AUTOSAR XML (schema 4-3-0)
package /Impl_SWC_OUTP_ARPkg
  swc implementation Impl_SWC_OUTP_type: programming-language=C, sw-version=1.0.0, vendor-id=0, behavior=SWC_OUTP_type_IB
    code-descriptors:
      code SRC: artifact-descriptors=autosar-engineering-object={short-label=EngObject, category=SWSRC}
    resource consumption ResourceConsumption
      memory section Mem_SWC_OUTP_CAL: size=0, sw-addrmethod=CAL, symbol=CAL
      memory section Mem_SWC_OUTP_CODE: size=0, sw-addrmethod=CODE, symbol=CODE
package /Impl_Type_OUTP_ARPkg
  6 x impl type:
    BOUTP_outputs: category=STRUCTURE
      956 x element, all with category=TYPE_REFERENCE:
        VOUTP_EACEnDemand_enum: implementation-data-type=uint8
        VOUTP_CACTempOverHigh_flg: implementation-data-type=boolean
        VOUTP_CACPresWarn_flg: implementation-data-type=boolean
        VOUTP_CACPresReady_flg: implementation-data-type=boolean
        VOUTP_EHPSEnDemand_enum: implementation-data-type=uint8
        VOUTP_CACOverrun_flg: implementation-data-type=boolean
        VOUTP_CACRunFail_flg: implementation-data-type=boolean
        VOUTP_CACFanReq_flg: implementation-data-type=boolean
        VOUTP_EHPSMotorDemSpd_rpm: implementation-data-type=float32
        VOUTP_EHPSSpdDemTimeout_flg: implementation-data-type=boolean
        VOUTP_EHPSEnTimeout_flg: implementation-data-type=boolean
        VOUTP_EHPSDisEnTimeout_flg: implementation-data-type=boolean
        VOUTP_DCDCEnDemamd_enum: implementation-data-type=uint8
        VOUTP_EHPSSpdCtrlMode_enum: implementation-data-type=float32
        VOUTP_EACSpdDemand_rpm: implementation-data-type=float32
        VOUTP_VehSpeed_kph: implementation-data-type=float32
        VOUTP_VehSpeedTimeOut_flg: implementation-data-type=boolean
        VOUTP_FSOffSw_enum: implementation-data-type=uint8
        VOUTP_FSOffSwTimeOut_flg: implementation-data-type=boolean
        VOUTP_ChrgPlugSta_enum: implementation-data-type=uint8
        VOUTP_PASDRMR_cm: implementation-data-type=uint8
        VOUTP_PASDRML_cm: implementation-data-type=uint8
        VOUTP_PASDRCR_cm: implementation-data-type=uint8
        VOUTP_PASDRCL_cm: implementation-data-type=uint8
        VOUTP_PASDFMR_cm: implementation-data-type=uint8
        VOUTP_PASDFML_cm: implementation-data-type=uint8
        VOUTP_PASDFCR_cm: implementation-data-type=uint8
        VOUTP_PASDFCL_cm: implementation-data-type=uint8
        VOUTP_APSDRLR_cm: implementation-data-type=uint16
        VOUTP_APSDRLL_cm: implementation-data-type=uint16
        VOUTP_APSDFLR_cm: implementation-data-type=uint16
        VOUTP_APSDFLL_cm: implementation-data-type=uint16
        VOUTP_PASAFCL_enum: implementation-data-type=uint8
        VOUTP_PASARMR_enum: implementation-data-type=uint8
        VOUTP_PASARML_enum: implementation-data-type=uint8
        VOUTP_PASARCR_enum: implementation-data-type=uint8
        VOUTP_PASARCL_enum: implementation-data-type=uint8
        VOUTP_PASAFMR_enum: implementation-data-type=uint8
        VOUTP_PASAFML_enum: implementation-data-type=uint8
        VOUTP_PASAFCR_enum: implementation-data-type=uint8
        VOUTP_USSStaRMR_flg: implementation-data-type=boolean
        VOUTP_USSStaRML_flg: implementation-data-type=boolean
        VOUTP_USSStaRLR_flg: implementation-data-type=boolean
        VOUTP_USSStaRLL_flg: implementation-data-type=boolean
        VOUTP_USSStaRCR_flg: implementation-data-type=boolean
        VOUTP_USSStaRCL_flg: implementation-data-type=boolean
        VOUTP_USSStaFMR_flg: implementation-data-type=boolean
        VOUTP_USSStaFML_flg: implementation-data-type=boolean
        VOUTP_USSStaFLR_flg: implementation-data-type=boolean
        VOUTP_USSStaFLL_flg: implementation-data-type=boolean
        VOUTP_USSStaFCR_flg: implementation-data-type=boolean
        VOUTP_USSStaFCL_flg: implementation-data-type=boolean
        VOUTP_Chime_enum: implementation-data-type=uint8
        VOUTP_SNSRLayout_enum: implementation-data-type=uint8
        VOUTP_StaFSya_flg: implementation-data-type=boolean
        VOUTP_ModOperation_enum: implementation-data-type=uint8
        VOUTP_BrkPedalPos_pct: implementation-data-type=float32
        VOUTP_BrkPedalPosTimeOut_flg: implementation-data-type=boolean
        VOUTP_LFRawWhlSpeed_kph: implementation-data-type=float32
        VOUTP_LFRawWhlSpeedTimeOut_flg: implementation-data-type=boolean
        VOUTP_RFRawWhlSpeed_kph: implementation-data-type=float32
        VOUTP_RFRawWhlSpeedTimeOut_flg: implementation-data-type=boolean
        VOUTP_LRRawWhlSpeed_kph: implementation-data-type=float32
        VOUTP_LRRawWhlSpeedTimeOut_flg: implementation-data-type=boolean
        VOUTP_RRRawWhlSpeed_kph: implementation-data-type=float32
        VOUTP_RRRawWhlSpeedTimeOut_flg: implementation-data-type=boolean
        VOUTP_LFRawWhlSpeedV_flg: implementation-data-type=boolean
        VOUTP_LFRawWhlSpeedVTimeOut_flg: implementation-data-type=boolean
        VOUTP_RFRawWhlSpeedV_flg: implementation-data-type=boolean
        VOUTP_RFRawWhlSpeedVTimeOut_flg: implementation-data-type=boolean
        VOUTP_LRRawWhlSpeedV_flg: implementation-data-type=boolean
        VOUTP_LRRawWhlSpeedVTimeOut_flg: implementation-data-type=boolean
        VOUTP_RRRawWhlSpeedV_flg: implementation-data-type=boolean
        VOUTP_RRRawWhlSpeedVTimeOut_flg: implementation-data-type=boolean
        VOUTP_LFWhlRotDir_enum: implementation-data-type=uint8
        VOUTP_LFWhlRotDirTimeOut_flg: implementation-data-type=boolean
        VOUTP_RFWhlRotDir_enum: implementation-data-type=uint8
        VOUTP_RFWhlRotDirTimeOut_flg: implementation-data-type=boolean
        VOUTP_LRWhlRotDir_enum: implementation-data-type=uint8
        VOUTP_LRWhlRotDirTimeOut_flg: implementation-data-type=boolean
        VOUTP_RRWhlRotDir_enum: implementation-data-type=uint8
        VOUTP_RRWhlRotDirTimeOut_flg: implementation-data-type=boolean
        VOUTP_LFPulseCountV_flg: implementation-data-type=boolean
        VOUTP_LFPulseCountVTimeOut_flg: implementation-data-type=boolean
        VOUTP_RFPulseCountV_flg: implementation-data-type=boolean
        VOUTP_RFPulseCountVTimeOut_flg: implementation-data-type=boolean
        VOUTP_LRPulseCountV_flg: implementation-data-type=boolean
        VOUTP_LRPulseCountVTimeOut_flg: implementation-data-type=boolean
        VOUTP_RRPulseCountV_flg: implementation-data-type=boolean
        VOUTP_RRPulseCountVTimeOut_flg: implementation-data-type=boolean
        VOUTP_LFPulseCount_enum: implementation-data-type=uint8
        VOUTP_LFPulseCountTimeOut_flg: implementation-data-type=boolean
        VOUTP_RFPulseCount_enum: implementation-data-type=uint8
        VOUTP_RFPulseCountTimeOut_flg: implementation-data-type=boolean
        VOUTP_LRPulseCount_enum: implementation-data-type=uint8
        VOUTP_LRPulseCountTimeOut_flg: implementation-data-type=boolean
        VOUTP_RRPulseCount_enum: implementation-data-type=uint8
        VOUTP_RRPulseCountTimeOut_flg: implementation-data-type=boolean
        VOUTP_ShifterHandleCmd_enum: implementation-data-type=uint8
        VOUTP_ShifterHandleCmdTimeOut_flg: implementation-data-type=boolean
        VOUTP_DriIntend_enum: implementation-data-type=uint8
        VOUTP_DriIntendTimeOut_flg: implementation-data-type=boolean
        VOUTP_EPSAOIControl_enum: implementation-data-type=uint8
        VOUTP_EPSAOIControlTimeOut_flg: implementation-data-type=boolean
        VOUTP_SASAngle_Deg: implementation-data-type=float32
        VOUTP_SASAngleTimeOut_flg: implementation-data-type=boolean
        VOUTP_SASSpeed_degps: implementation-data-type=float32
        VOUTP_SASSpeedTimeOut_flg: implementation-data-type=boolean
        VOUTP_SASSpeedValid_flg: implementation-data-type=boolean
        VOUTP_SASSpeedValidTimeOut_flg: implementation-data-type=boolean
        VOUTP_SASCAL_flg: implementation-data-type=boolean
        VOUTP_SASCALTimeOut_flg: implementation-data-type=boolean
        VOUTP_SASV_flg: implementation-data-type=boolean
        VOUTP_SASVTimeOut_flg: implementation-data-type=boolean
        VOUTP_GRADE_Deg: implementation-data-type=float32
        VOUTP_GRADETimeOut_flg: implementation-data-type=boolean
        VOUTP_YawRate_degps: implementation-data-type=float32
        VOUTP_YawRateTimeOut_flg: implementation-data-type=boolean
        VOUTP_LatAccel_Gps: implementation-data-type=float32
        VOUTP_LatAccelTimeOut_flg: implementation-data-type=boolean
        VOUTP_LongAccel_Gps: implementation-data-type=float32
        VOUTP_LongAccelTimeOut_flg: implementation-data-type=boolean
        VOUTP_MCPressure_bar: implementation-data-type=float32
        VOUTP_MCPressureTimeOut_flg: implementation-data-type=boolean
        VOUTP_YawRateV_flg: implementation-data-type=boolean
        VOUTP_YawRateVTimeOut_flg: implementation-data-type=boolean
        VOUTP_LatAccelV_flg: implementation-data-type=boolean
        VOUTP_LatAccelVTimeOut_flg: implementation-data-type=boolean
        VOUTP_LongAccelV_flg: implementation-data-type=boolean
        VOUTP_LongAccelVTimeOut_flg: implementation-data-type=boolean
        VOUTP_MCPressureV_bar: implementation-data-type=boolean
        VOUTP_MCPressureVTimeOut_flg: implementation-data-type=boolean
        VOUTP_BrkSwSta_flg: implementation-data-type=boolean
        VOUTP_BrkSwStaTimeOut_flg: implementation-data-type=boolean
        VOUTP_BrkSwV_flg: implementation-data-type=boolean
        VOUTP_BrkSwVTimeOut_flg: implementation-data-type=boolean
        VOUTP_ESCStandstill_flg: implementation-data-type=boolean
        VOUTP_ESCStandstillTimeOut_flg: implementation-data-type=boolean
        VOUTP_ESCAPSSta_enum: implementation-data-type=uint8
        VOUTP_ESCAPSStaTimeOut_flg: implementation-data-type=boolean
        VOUTP_EPBExtReleaseAvail_flg: implementation-data-type=boolean
        VOUTP_EPBExtReleaseAvailTimeOut_flg: implementation-data-type=boolean
        VOUTP_EPBExtApplyAvail_flg: implementation-data-type=boolean
        VOUTP_EPBExtApplyAvailTimeOut_flg: implementation-data-type=boolean
        VOUTP_EPBErrSta_enum: implementation-data-type=uint8
        VOUTP_EPBErrStaTimeOut_flg: implementation-data-type=boolean
        VOUTP_EPBSta_enum: implementation-data-type=uint8
        VOUTP_EPBStaTimeOut_flg: implementation-data-type=boolean
        VOUTP_AVMparkingcancel_enum: implementation-data-type=uint8
        VOUTP_AVMparkingcancelTimeOut_flg: implementation-data-type=boolean
        VOUTP_AVMparkingexcute_enum: implementation-data-type=uint8
        VOUTP_AVMparkingexcuteTimeOut_flg: implementation-data-type=boolean
        VOUTP_AVMParkingmode_enum: implementation-data-type=uint8
        VOUTP_AVMParkingmodeTimeOut_flg: implementation-data-type=boolean
        VOUTP_AVMErrSTA_flg: implementation-data-type=boolean
        VOUTP_AVMErrSTATimeOut_flg: implementation-data-type=boolean
        VOUTP_IVIStatus_flg: implementation-data-type=boolean
        VOUTP_IVIStatusTimeOut_flg: implementation-data-type=boolean
        VOUTP_CAASSw_enum: implementation-data-type=uint8
        VOUTP_CAASSwTimeOut_flg: implementation-data-type=boolean
        VOUTP_IVIScreen_enum: implementation-data-type=uint8
        VOUTP_IVIScreenTimeOut_flg: implementation-data-type=boolean
        VOUTP_ABSActive_flg: implementation-data-type=boolean
        VOUTP_ABSActiveTimeOut_flg: implementation-data-type=boolean
        VOUTP_TCSActive_flg: implementation-data-type=boolean
        VOUTP_TCSActiveTimeOut_flg: implementation-data-type=boolean
        VOUTP_DriverSeatBeltCmd_flg: implementation-data-type=boolean
        VOUTP_DriverSeatBeltCmdTimeOut_flg: implementation-data-type=boolean
        VOUTP_APSProgressPCT_pct: implementation-data-type=float32
        VOUTP_APSRQDisplay_enum: implementation-data-type=uint8
        VOUTP_APSSWVer_enum: implementation-data-type=uint8
        VOUTP_APSHWVer_enum: implementation-data-type=uint8
        VOUTP_APSExitCondition_enum: implementation-data-type=uint8
        VOUTP_APSAngleTarget_Deg: implementation-data-type=float32
        VOUTP_APSVRqEPASCtrl_flg: implementation-data-type=boolean
        VOUTP_APSRqEPASCtrl_flg: implementation-data-type=boolean
        VOUTP_CAASSta_enum: implementation-data-type=uint8
        VOUTP_DKCPDkeyAreaRAPSSta_enum: implementation-data-type=uint8
        VOUTP_DKCParkingModeCmd_enum: implementation-data-type=uint8
        VOUTP_PUIDLowPower_flg: implementation-data-type=boolean
        VOUTP_CAASVMCReqA_flg: implementation-data-type=boolean
        VOUTP_APSShiftPosnReq_enum: implementation-data-type=uint8
        VOUTP_APSSpeedCMD_kph: implementation-data-type=float32
        VOUTP_APSVMCReqA_flg: implementation-data-type=boolean
        VOUTP_RAPSBCMLamp_enum: implementation-data-type=uint8
        VOUTP_RAPSBCMLockReq_flg: implementation-data-type=boolean
        VOUTP_APSPwrReq_enum: implementation-data-type=uint8
        VOUTP_RAPSErrWarnSta_enum: implementation-data-type=uint8
        VOUTP_RAPSErrLv1_flg: implementation-data-type=boolean
        VOUTP_IVIUserTakeOverAPSSta_flg: implementation-data-type=boolean
        VOUTP_FDCBCMLBeamCmd_flg: implementation-data-type=boolean
        VOUTP_FDCBCMPLampCmd_flg: implementation-data-type=boolean
        VOUTP_FDCBCMHBeamCmd_flg: implementation-data-type=boolean
        VOUTP_FDCBCMSMKLCmd_flg: implementation-data-type=boolean
        VOUTP_FDCBCMSMKRCmd_flg: implementation-data-type=boolean
        VOUTP_FDCBCMDVRSignalLCmd_flg: implementation-data-type=boolean
        VOUTP_FDCBCMDVRSignalRCmd_flg: implementation-data-type=boolean
        VOUTP_FDCBCMBSDBuzzerCmd_flg: implementation-data-type=boolean
        VOUTP_FDCBCMSLTLpCmd_flg: implementation-data-type=boolean
        VOUTP_FDCBCMSRTLpCmd_flg: implementation-data-type=boolean
        VOUTP_FDCBCMLTurnLpCmd_flg: implementation-data-type=boolean
        VOUTP_FDCBCMRTurnLpCmd_flg: implementation-data-type=boolean
        VOUTP_FDCBCMStopINDCmd_flg: implementation-data-type=boolean
        VOUTP_FDCBCMSTOPBALLCmd_flg: implementation-data-type=boolean
        VOUTP_FDCBCMInnerCallBellCmd_flg: implementation-data-type=boolean
        VOUTP_FDCBCMCallBellCmd_flg: implementation-data-type=boolean
        VOUTP_FDCBCMWiperHCmd_flg: implementation-data-type=boolean
        VOUTP_FDCBCMWasherCmd_flg: implementation-data-type=boolean
        VOUTP_FDCBCMWiperLCmd_flg: implementation-data-type=boolean
        VOUTP_FDCBCMLDRLCmd_flg: implementation-data-type=boolean
        VOUTP_FDCBCMRDRLCmd_flg: implementation-data-type=boolean
        VOUTP_FDCBCMRFLampCmd_flg: implementation-data-type=boolean
        VOUTP_TurnLpPatternSta_enum: implementation-data-type=uint8
        VOUTP_FDCBCMFDoorSta_flg: implementation-data-type=boolean
        VOUTP_FDCBCMMDoorSta_flg: implementation-data-type=boolean
        VOUTP_FDCBCMRDoorSta_flg: implementation-data-type=boolean
        VOUTP_FDCBCMRoomLpAmbCmd_flg: implementation-data-type=boolean
        VOUTP_FDCBCMLBSDRCmd_flg: implementation-data-type=boolean
        VOUTP_FDCBCMLBSDYCmd_flg: implementation-data-type=boolean
        VOUTP_FDCBCMRBSDRCmd_flg: implementation-data-type=boolean
        VOUTP_FDCBCMRBSDYCmd_flg: implementation-data-type=boolean
        VOUTP_FDCBCMEmExitSWSta_flg: implementation-data-type=boolean
        VOUTP_InnerBuzzerModeSta_enum: implementation-data-type=uint8
        VOUTP_FDCBCMInnerBuzzerCmd_flg: implementation-data-type=boolean
        VOUTP_FDCBCMRoomLpAmbSetSta_flg: implementation-data-type=boolean
        VOUTP_FDCBCMRoomLpSetSta_flg: implementation-data-type=boolean
        VOUTP_FDCBCMFRoomLpSetSta_pct: implementation-data-type=uint8
        VOUTP_FDCBCMFRoomLpCmd_pct: implementation-data-type=uint8
        VOUTP_FDCBCMMRoomLpSetSta_pct: implementation-data-type=uint8
        VOUTP_FDCBCMMRoomLpCmd_pct: implementation-data-type=uint8
        VOUTP_FDCBCMRRoomLpSetSta_pct: implementation-data-type=uint8
        VOUTP_FDCBCMRRoomLpCmd_pct: implementation-data-type=uint8
        VOUTP_FDCBCMHelpINDCmd_flg: implementation-data-type=boolean
        VOUTP_FDCBCMOSDrOpenSWSta_enum: implementation-data-type=uint8
        VOUTP_FDCBCMEmSVCmd_flg: implementation-data-type=boolean
        VOUTP_FDCBCMFDOpenSVCmd_flg: implementation-data-type=boolean
        VOUTP_FDCBCMFDCloseSVCmd_flg: implementation-data-type=boolean
        VOUTP_FDCBCMMDOpenSVCmd_flg: implementation-data-type=boolean
        VOUTP_FDCBCMMDCloseSVCmd_flg: implementation-data-type=boolean
        VOUTP_FDCBCMLTurnSWSta_flg: implementation-data-type=boolean
        VOUTP_FDCBCMRTurnSWSta_flg: implementation-data-type=boolean
        VOUTP_FDCBCMRGearSta_flg: implementation-data-type=boolean
        VOUTP_FDCBCMBrakeCmd_flg: implementation-data-type=boolean
        VOUTP_FDCBCMTurnBuzzerENSta_flg: implementation-data-type=boolean
        VOUTP_WakeUp_flg: implementation-data-type=boolean
        VOUTP_KeepWakeUp_flg: implementation-data-type=boolean
        VOUTP_C3BMS6RCDTC_raw32: implementation-data-type=uint32
        VOUTP_C3BMS6CSDTC_raw32: implementation-data-type=uint32
        VOUTP_C3BMS6LCDTC_raw32: implementation-data-type=uint32
        VOUTP_C3BMS1RCDTC_raw32: implementation-data-type=uint32
        VOUTP_C3BMS1CSDTC_raw32: implementation-data-type=uint32
        VOUTP_C3BMS1LCDTC_raw32: implementation-data-type=uint32
        VOUTP_C3CCU1RCDTC_raw32: implementation-data-type=uint32
        VOUTP_C3CCU1CSDTC_raw32: implementation-data-type=uint32
        VOUTP_C3CCU1LCDTC_raw32: implementation-data-type=uint32
        VOUTP_C3CCU2RCDTC_raw32: implementation-data-type=uint32
        VOUTP_C3CCU2CSDTC_raw32: implementation-data-type=uint32
        VOUTP_C3CCU2LCDTC_raw32: implementation-data-type=uint32
        VOUTP_C1ABM1RCDTC_raw32: implementation-data-type=uint32
        VOUTP_C1ABM1CSDTC_raw32: implementation-data-type=uint32
        VOUTP_C1ABM1LCDTC_raw32: implementation-data-type=uint32
        VOUTP_Lv{1..4}ErrDTC_raw32: implementation-data-type=uint32
        VOUTP_BrkSWErrDTC_raw32: implementation-data-type=uint32
        VOUTP_BrkSWNoBacDTC_raw32: implementation-data-type=uint32
        VOUTP_KeyAuthDTC_raw32: implementation-data-type=uint32
        VOUTP_ONtoRdyDTC_raw32: implementation-data-type=uint32
        VOUTP_HVB4PreDTC_raw32: implementation-data-type=uint32
        VOUTP_MCU4PreDTC_raw32: implementation-data-type=uint32
        VOUTP_DCDC4PreDTC_raw32: implementation-data-type=uint32
        VOUTP_HVRlyCloDTC_raw32: implementation-data-type=uint32
        VOUTP_BMSRdyDTC_raw32: implementation-data-type=uint32
        VOUTP_DCDCEnaDTC_raw32: implementation-data-type=uint32
        VOUTP_HiLvSaChkDTC_raw32: implementation-data-type=uint32
        VOUTP_MidLvSaChkDTC_raw32: implementation-data-type=uint32
        VOUTP_MCUDisDTC_raw32: implementation-data-type=uint32
        VOUTP_DCDCDisDTC_raw32: implementation-data-type=uint32
        VOUTP_HVRlyOpDTC_raw32: implementation-data-type=uint32
        VOUTP_MCUActDTC_raw32: implementation-data-type=uint32
        VOUTP_OBC4PreDTC_raw32: implementation-data-type=uint32
        VOUTP_IniLVLoDTC_raw32: implementation-data-type=uint32
        VOUTP_LVSupLoDTC_raw32: implementation-data-type=uint32
        VOUTP_LVSupHiDTC_raw32: implementation-data-type=uint32
        VOUTP_DrStSWDTC_raw32: implementation-data-type=uint32
        VOUTP_FLDoorSWDTC_raw32: implementation-data-type=uint32
        VOUTP_RLDoorSWDTC_raw32: implementation-data-type=uint32
        VOUTP_FRDoorSWDTC_raw32: implementation-data-type=uint32
        VOUTP_RRDoorSWDTC_raw32: implementation-data-type=uint32
        VOUTP_HoodSWDTC_raw32: implementation-data-type=uint32
        VOUTP_TailgaSWDTC_raw32: implementation-data-type=uint32
        VOUTP_EDriveSysErrVCUErr_flg: implementation-data-type=boolean
        VOUTP_VehMalfunLevel_enum: implementation-data-type=uint8
        VOUTP_APS1SigOoRDTC_raw32: implementation-data-type=uint32
        VOUTP_APS2SigOoRDTC_raw32: implementation-data-type=uint32
        VOUTP_APSCorrErrDTC_raw32: implementation-data-type=uint32
        VOUTP_MCUF1NoComDTC_raw32: implementation-data-type=uint32
        VOUTP_MCUR1NoComDTC_raw32: implementation-data-type=uint32
        VOUTP_Shifter1NoComDTC_raw32: implementation-data-type=uint32
        VOUTP_ESC7NoComDTC_raw32: implementation-data-type=uint32
        VOUTP_ESC1NoComDTC_raw32: implementation-data-type=uint32
        VOUTP_ESC5NoComDTC_raw32: implementation-data-type=uint32
        VOUTP_EnterNewOperCyc_flg: implementation-data-type=boolean
        VOUTP_DiagHCrashDTC_raw32: implementation-data-type=uint32
        VOUTP_DiagFLTSDTC_raw32: implementation-data-type=uint32
        VOUTP_DiagFRTSDTC_raw32: implementation-data-type=uint32
        VOUTP_DiagRLTSDTC_raw32: implementation-data-type=uint32
        VOUTP_DiagRRTSDTC_raw32: implementation-data-type=uint32
        VOUTP_FCLUSSDTC_raw32: implementation-data-type=uint32
        VOUTP_FMLUSSDTC_raw32: implementation-data-type=uint32
        VOUTP_FMRUSSDTC_raw32: implementation-data-type=uint32
        VOUTP_FCRUSSDTC_raw32: implementation-data-type=uint32
        VOUTP_RCLUSSDTC_raw32: implementation-data-type=uint32
        VOUTP_RMLUSSDTC_raw32: implementation-data-type=uint32
        VOUTP_RMRUSSDTC_raw32: implementation-data-type=uint32
        VOUTP_RCRUSSDTC_raw32: implementation-data-type=uint32
        VOUTP_FLLUSSDTC_raw32: implementation-data-type=uint32
        VOUTP_FLRUSSDTC_raw32: implementation-data-type=uint32
        VOUTP_RLLUSSDTC_raw32: implementation-data-type=uint32
        VOUTP_RLRUSSDTC_raw32: implementation-data-type=uint32
        VOUTP_FCM2NoComDTC_raw32: implementation-data-type=uint32
        VOUTP_FCM2RCErrDTC_raw32: implementation-data-type=uint32
        VOUTP_FCM2CSErrDTC_raw32: implementation-data-type=uint32
        VOUTP_FCM3NoComDTC_raw32: implementation-data-type=uint32
        VOUTP_FCM3RCErrDTC_raw32: implementation-data-type=uint32
        VOUTP_FCM3CSErrDTC_raw32: implementation-data-type=uint32
        VOUTP_FCM4NoComDTC_raw32: implementation-data-type=uint32
        VOUTP_FCM4CSErrDTC_raw32: implementation-data-type=uint32
        VOUTP_FCM5NoComDTC_raw32: implementation-data-type=uint32
        VOUTP_FCM5CSErrDTC_raw32: implementation-data-type=uint32
        VOUTP_ZoneSCPNoComDTC_raw32: implementation-data-type=uint32
        VOUTP_BMSSigErrDetDTC_raw32: implementation-data-type=uint32
        VOUTP_FCMACCSigErrDetDTC_raw32: implementation-data-type=uint32
        VOUTP_FrMCUSigErrDetDTC_raw32: implementation-data-type=uint32
        VOUTP_RrMCUSigErrDetDTC_raw32: implementation-data-type=uint32
        VOUTP_CCUSigErrDetDTC_raw32: implementation-data-type=uint32
        VOUTP_ACCAccelCmdErrDetDTC_raw32: implementation-data-type=uint32
        VOUTP_ACCMalfuncDetDTC_raw32: implementation-data-type=uint32
        VOUTP_CCMalfuncDetDTC_raw32: implementation-data-type=uint32
        VOUTP_MSAMalfuncDetDTC_raw32: implementation-data-type=uint32
        VOUTP_ISAMalfuncDetDTC_raw32: implementation-data-type=uint32
        VOUTP_MCUF1RCErrDTC_raw32: implementation-data-type=uint32
        VOUTP_MCUR1RCErrDTC_raw32: implementation-data-type=uint32
        VOUTP_MCUF1CSErrDTC_raw32: implementation-data-type=uint32
        VOUTP_MCUR1CSErrDTC_raw32: implementation-data-type=uint32
        VOUTP_Shifter1RCErrDTC_raw32: implementation-data-type=uint32
        VOUTP_Shifter1CSErrDTC_raw32: implementation-data-type=uint32
        VOUTP_ESC7RCErrDTC_raw32: implementation-data-type=uint32
        VOUTP_ESC7CSErrDTC_raw32: implementation-data-type=uint32
        VOUTP_ESC1RCErrDTC_raw32: implementation-data-type=uint32
        VOUTP_ESC1CSErrDTC_raw32: implementation-data-type=uint32
        VOUTP_ESC5RCErrDTC_raw32: implementation-data-type=uint32
        VOUTP_ESC5CSErrDTC_raw32: implementation-data-type=uint32
        VOUTP_FrMCUTqErrDTC_raw32: implementation-data-type=uint32
        VOUTP_RrMCUTqErrDTC_raw32: implementation-data-type=uint32
        VOUTP_LFBatwarnDTC_raw32: implementation-data-type=uint32
        VOUTP_RFBatwarnDTC_raw32: implementation-data-type=uint32
        VOUTP_LRBatwarnDTC_raw32: implementation-data-type=uint32
        VOUTP_RRBatwarnDTC_raw32: implementation-data-type=uint32
        VOUTP_LFPressIndiDTC_raw32: implementation-data-type=uint32
        VOUTP_RFPressIndiDTC_raw32: implementation-data-type=uint32
        VOUTP_LRPressIndiDTC_raw32: implementation-data-type=uint32
        VOUTP_RRPressIndiDTC_raw32: implementation-data-type=uint32
        VOUTP_LFWheelTmpHighDTC_raw32: implementation-data-type=uint32
        VOUTP_RFWheelTmpHighDTC_raw32: implementation-data-type=uint32
        VOUTP_LRWheelTmpHighDTC_raw32: implementation-data-type=uint32
        VOUTP_RRWheelTmpHighDTC_raw32: implementation-data-type=uint32
        VOUTP_LFSensorFailDTC_raw32: implementation-data-type=uint32
        VOUTP_RFSensorFailDTC_raw32: implementation-data-type=uint32
        VOUTP_LRSensorFailDTC_raw32: implementation-data-type=uint32
        VOUTP_RRSensorFailDTC_raw32: implementation-data-type=uint32
        VOUTP_C1EPAS2LCDTC_raw32: implementation-data-type=uint32
        VOUTP_5vAPS1PwrErrDTC_raw32: implementation-data-type=uint32
        VOUTP_5vAPS2PwrErrDTC_raw32: implementation-data-type=uint32
        VOUTP_EPBLockTODTC_raw32: implementation-data-type=uint32
        VOUTP_EPBUnlockTODTC_raw32: implementation-data-type=uint32
        VOUTP_LimpHomeActTmp_flg: implementation-data-type=boolean
        VOUTP_DTCDetect_enum: implementation-data-type=uint8
        VOUTP_EngagePFail_flg: implementation-data-type=boolean
        VOUTP_DisengagePFail_flg: implementation-data-type=boolean
        VOUTP_VCURAPSErrLv2_flg: implementation-data-type=boolean
        VOUTP_VCURAPSErrLv3_flg: implementation-data-type=boolean
        VOUTP_EDriveSysErrShifterErr_flg: implementation-data-type=boolean
        VOUTP_LVSysErrPwrOutErr_flg: implementation-data-type=boolean
        VOUTP_HVRlyOpFail_flg: implementation-data-type=boolean
        VOUTP_MCUActDisFail_flg: implementation-data-type=boolean
        VOUTP_VCUBrkSWSta_enum: implementation-data-type=uint8
        VOUTP_VCUFLDoorSta_flg: implementation-data-type=boolean
        VOUTP_VCUFRDoorSta_flg: implementation-data-type=boolean
        VOUTP_VCURLDoorSta_flg: implementation-data-type=boolean
        VOUTP_VCURRDoorSta_flg: implementation-data-type=boolean
        VOUTP_SysAllowReadySta_flg: implementation-data-type=boolean
        VOUTP_VCUHoodSWSta_flg: implementation-data-type=boolean
        VOUTP_VCUTailgateSWSta_flg: implementation-data-type=boolean
        VOUTP_ActAPSPosn_pct: implementation-data-type=float32
        VOUTP_EAPS1MIN_pct: implementation-data-type=float32
        VOUTP_EAPS2MIN_pct: implementation-data-type=float32
        VOUTP_ResetPedalZeroPosStart_flg: implementation-data-type=boolean
        VOUTP_EAPS1NRM_pct: implementation-data-type=float32
        VOUTP_EAPS2NRM_pct: implementation-data-type=float32
        VOUTP_VSS_kph: implementation-data-type=float32
        VOUTP_RUNTM_s: implementation-data-type=uint16
        VOUTP_MILDIST_km: implementation-data-type=float32
        VOUTP_WARMUPS_cnt: implementation-data-type=uint8
        VOUTP_CLRDIST_km: implementation-data-type=float32
        VOUTP_APPD_pct: implementation-data-type=float32
        VOUTP_APPE_pct: implementation-data-type=float32
        VOUTP_MILTIME_min: implementation-data-type=uint16
        VOUTP_CLRTIME_min: implementation-data-type=uint16
        VOUTP_BATSOC_pct: implementation-data-type=float32
        VOUTP_HEVBATT_V: implementation-data-type=float32
        VOUTP_ODOMETER_km: implementation-data-type=float32
        VOUTP_BATSOH_pct: implementation-data-type=float32
        VOUTP_HVBCellVoltMin_V: implementation-data-type=float32
        VOUTP_HVBCellVoltMax_V: implementation-data-type=float32
        VOUTP_HVESSCHARGELIM_kW: implementation-data-type=float32
        VOUTP_HVESSCHARGEACT_kW: implementation-data-type=float32
        VOUTP_HVESSENER_Whps: implementation-data-type=float32
        VOUTP_NUMPSATRIPSFLTMEMCLR_cnt: implementation-data-type=uint16
        VOUTP_HVBattCurr_Ahps: implementation-data-type=float32
        VOUTP_PSAR_sec: implementation-data-type=uint32
        VOUTP_PSAL_sec: implementation-data-type=uint32
        VOUTP_IPSAR_sec: implementation-data-type=uint32
        VOUTP_IPSAL_sec: implementation-data-type=uint32
        VOUTP_CPSAR_sec: implementation-data-type=uint32
        VOUTP_CPSAL_sec: implementation-data-type=uint32
        VOUTP_HVBNAH_Ahr: implementation-data-type=float32
        VOUTP_HVBNE_kWh: implementation-data-type=float32
        VOUTP_IGNCNTR_cnt: implementation-data-type=uint16
        VOUTP_TNBCPSAR_Ahr: implementation-data-type=float32
        VOUTP_TNBCPSAL_Ahr: implementation-data-type=float32
        VOUTP_TNECPSAR_kWh: implementation-data-type=float32
        VOUTP_TNECPSAL_kWh: implementation-data-type=float32
        VOUTP_TEBPSAR_kWh: implementation-data-type=float32
        VOUTP_TEBPSAL_kWh: implementation-data-type=float32
        VOUTP_TGEOVCR_kWh: implementation-data-type=float32
        VOUTP_TGEOVCL_kWh: implementation-data-type=float32
        VOUTP_GECHGOVCDCR_kWh: implementation-data-type=float32
        VOUTP_GECHGOVCDCL_kWh: implementation-data-type=float32
        VOUTP_GECHGOVCACR_kWh: implementation-data-type=float32
        VOUTP_GECHGOVCACL_kWh: implementation-data-type=float32
        VOUTP_RESSV2XENNONPSAR_kWh: implementation-data-type=float32
        VOUTP_RESSV2XENNONPSAL_kWh: implementation-data-type=float32
        VOUTP_PKER_kphsqr: implementation-data-type=float32
        VOUTP_PKEL_kphsqr: implementation-data-type=float32
        VOUTP_ResetCDEODTR_km: implementation-data-type=float32
        VOUTP_CDEODTR_km: implementation-data-type=float32
        VOUTP_CDEODTL_km: implementation-data-type=float32
        VOUTP_AvgBattTempPSAR_C: implementation-data-type=float32
        VOUTP_AvgBattTempPSAL_C: implementation-data-type=float32
        VOUTP_AvgBattTempOVCR_C: implementation-data-type=float32
        VOUTP_AvgBattTempOVCL_C: implementation-data-type=float32
        VOUTP_AvgBattTempOFFR_C: implementation-data-type=float32
        VOUTP_AvgBattTempOFFL_C: implementation-data-type=float32
        VOUTP_QTYPSATRIPSR_cnt: implementation-data-type=uint32
        VOUTP_QTYPSATRIPSL_cnt: implementation-data-type=uint32
        VOUTP_RESSCNTDODRNGR_cnt: implementation-data-type=u16_Array8_type
        VOUTP_RESSCNTDODRNGL_cnt: implementation-data-type=u16_Array8_type
        VOUTP_ETMATOER_kWh: implementation-data-type=float32
        VOUTP_ETMATOEL_kWh: implementation-data-type=float32
        VOUTP_ETMBTOER_kWh: implementation-data-type=float32
        VOUTP_ETMBTOEL_kWh: implementation-data-type=float32
        VOUTP_RESSTIMESOCPSARNGR_s: implementation-data-type=u32_Array8_type
        VOUTP_RESSTIMESOCPSARNGL_s: implementation-data-type=u32_Array8_type
        VOUTP_RESSTIMESOCCHGRNGR_s: implementation-data-type=u32_Array8_type
        VOUTP_RESSTIMESOCCHGRNGL_s: implementation-data-type=u32_Array8_type
        VOUTP_RESSTIMESOCOFFRNGR_s: implementation-data-type=u32_Array8_type
        VOUTP_RESSTIMESOCOFFRNGL_s: implementation-data-type=u32_Array8_type
        VOUTP_MAXBATTEMPL_C: implementation-data-type=float32
        VOUTP_MINBATTEMPL_C: implementation-data-type=float32
        VOUTP_AVGBATTEMPL_C: implementation-data-type=float32
        VOUTP_PROTOCOLID_enum: implementation-data-type=uint8
        VOUTP_RESSTTEMPRNGAXIS_enum: implementation-data-type=uint8
        VOUTP_RESSTIMESOCRNGAXIS_enum: implementation-data-type=uint8
        VOUTP_RESSCNTSDODRNGAXIS_enum: implementation-data-type=uint8
        VOUTP_CALID_cnt: implementation-data-type=u8_Array16_type
        VOUTP_ECUNAME_cnt: implementation-data-type=u8_Array20_type
        VOUTP_PKERNumerator_kphsqr: implementation-data-type=float32
        VOUTP_PKELNumerator_kphsqr: implementation-data-type=float32
        VOUTP_BattTempPSAR_sec: implementation-data-type=uint32
        VOUTP_BattTempPSAL_sec: implementation-data-type=uint32
        VOUTP_OVCR_sec: implementation-data-type=uint32
        VOUTP_OVCL_sec: implementation-data-type=uint32
        VOUTP_OFFR_sec: implementation-data-type=uint32
        VOUTP_OFFL_sec: implementation-data-type=uint32
        VOUTP_AVGBATTEMPL_sec: implementation-data-type=uint32
        VOUTP_VinCode_cnt: implementation-data-type=u8_Array17_type
        VOUTP_STASUP_enum: implementation-data-type=uint8
        VOUTP_HEVMODE_enum: implementation-data-type=uint8
        VOUTP_HVBATT_A: implementation-data-type=float32
        VOUTP_DIDModelVersion_raw: implementation-data-type=uint8
        VOUTP_DIDModelVersionChksum_raw: implementation-data-type=uint8
        VOUTP_DKCTimeSN_cnt: implementation-data-type=uint32
        VOUTP_DKCAuthSta_enum: implementation-data-type=uint8
        VOUTP_TimeSNDKCFbk_cnt: implementation-data-type=uint32
        VOUTP_KeyMissSta_flg: implementation-data-type=boolean
        VOUTP_KeyModeSta_enum: implementation-data-type=uint8
        VOUTP_DkeyShowIVISta_enum: implementation-data-type=uint8
        VOUTP_KeyAreaPS_enum: implementation-data-type=uint8
        VOUTP_KeyAreaLockUnlock_enum: implementation-data-type=uint8
        VOUTP_PCommandToBCM_enum: implementation-data-type=uint8
        VOUTP_DKeyWelcomeSta_enum: implementation-data-type=uint8
        VOUTP_KeyAreaPTG_enum: implementation-data-type=uint8
        VOUTP_KeyAreaSPTGSta_enum: implementation-data-type=uint8
        VOUTP_UIDLowPowerSta_enum: implementation-data-type=uint8
        VOUTP_DkeyAreaRAPSSta_enum: implementation-data-type=uint8
        VOUTP_ParkingModeCmd_enum: implementation-data-type=uint8
        VOUTP_KeyNumSta_enum: implementation-data-type=uint8
        VOUTP_KeyTypeSta_enum: implementation-data-type=uint8
        VOUTP_FDCDKCAllowSleep_flg: implementation-data-type=boolean
        VOUTP_JudgeKeepUnlockZone_flg: implementation-data-type=boolean
        VOUTP_DISCTurn_flg: implementation-data-type=boolean
        VOUTP_DISCTargetSpd_kph: implementation-data-type=float32
        VOUTP_DISCSta_enum: implementation-data-type=uint8
        VOUTP_DISCButtSta_flg: implementation-data-type=boolean
        VOUTP_AllCANTxReq_flg: implementation-data-type=boolean
        VOUTP_NMmTxReq_flg: implementation-data-type=boolean
        VOUTP_Awake_enum: implementation-data-type=uint8
        VOUTP_CSB_flg: implementation-data-type=boolean
        VOUTP_ErrorState_enum: implementation-data-type=uint8
        VOUTP_NodeID_enum: implementation-data-type=uint8
        VOUTP_PNI_flg: implementation-data-type=boolean
        VOUTP_RptMsgReq_flg: implementation-data-type=boolean
        VOUTP_WakeUp_enum: implementation-data-type=uint8
        VOUTP_ActiveWU_flg: implementation-data-type=boolean
        VOUTP_SysNMmSta_enum: implementation-data-type=uint8
        VOUTP_NetworkReq_flg: implementation-data-type=boolean
        VOUTP_SysPowerMode_enum: implementation-data-type=uint8
        VOUTP_PowerUpState_enum: implementation-data-type=uint8
        VOUTP_PowerDownState_enum: implementation-data-type=uint8
        VOUTP_ChrgState_enum: implementation-data-type=uint8
        VOUTP_PowerUpFault_enum: implementation-data-type=uint8
        VOUTP_PowerDownFault_enum: implementation-data-type=uint8
        VOUTP_ChrgFault_enum: implementation-data-type=uint8
        VOUTP_IRCRlyClose_flg: implementation-data-type=boolean
        VOUTP_IGNRlyClose_flg: implementation-data-type=boolean
        VOUTP_BattHVDem_enum: implementation-data-type=uint8
        VOUTP_DCDCRlyDem_enum: implementation-data-type=uint8
        VOUTP_CACRlyDem_enum: implementation-data-type=uint8
        VOUTP_MCUHVLoopDem_enum: implementation-data-type=uint8
        VOUTP_EHPSRlyDem_enum: implementation-data-type=uint8
        VOUTP_ACHVLoopDem_enum: implementation-data-type=uint8
        VOUTP_HVSysReady_enum: implementation-data-type=uint8
        VOUTP_DrivelineRelease_enum: implementation-data-type=uint8
        VOUTP_ActiveDischargeReq_enum: implementation-data-type=uint8
        VOUTP_VCUMCUEn_flg: implementation-data-type=boolean
        VOUTP_VCUMCUFailRst_flg: implementation-data-type=boolean
        VOUTP_HVILFail_flg: implementation-data-type=boolean
        VOUTP_LostHVComActivePwrDown_flg: implementation-data-type=boolean
        VOUTP_LVBattLowInd_enum: implementation-data-type=uint8
        VOUTP_ChrgPowerUpFail_flg: implementation-data-type=boolean
        VOUTP_ChrgBCUHVFail_flg: implementation-data-type=boolean
        VOUTP_HVFailureChkPass_flg: implementation-data-type=boolean
        VOUTP_HVILDetectFail_flg: implementation-data-type=boolean
        VOUTP_V2BLifeSig_cnt: implementation-data-type=uint8
        VOUTP_V2BAux{1..3}OnOff_enum: implementation-data-type=uint8
        VOUTP_V2BMainPosRlySta_enum: implementation-data-type=uint8
        VOUTP_V2BMainPosRlyFit_enum: implementation-data-type=uint8
        VOUTP_V2BACPosRlySta_enum: implementation-data-type=uint8
        VOUTP_V2BACPosRlyFit_enum: implementation-data-type=uint8
        VOUTP_V2BAirPosRlySta_enum: implementation-data-type=uint8
        VOUTP_V2BAirPosRlyFit_enum: implementation-data-type=uint8
        VOUTP_V2BOilPosRlySta_enum: implementation-data-type=uint8
        VOUTP_V2BOilPosRlyFit_enum: implementation-data-type=uint8
        VOUTP_V2BDCDCPosRlySta_enum: implementation-data-type=uint8
        VOUTP_V2BDCDCPosRlyFit_enum: implementation-data-type=uint8
        VOUTP_V2BAux1RlySta_enum: implementation-data-type=uint8
        VOUTP_V2BAux1RlyFit_enum: implementation-data-type=uint8
        VOUTP_V2BAux2RlySta_enum: implementation-data-type=uint8
        VOUTP_V2BAux2RlyFit_enum: implementation-data-type=uint8
        VOUTP_V2BAux3RlySta_enum: implementation-data-type=uint8
        VOUTP_V2BAux3RlyFit_enum: implementation-data-type=uint8
        VOUTP_V2BAux4RlySta_enum: implementation-data-type=uint8
        VOUTP_V2BAux4RlyFit_enum: implementation-data-type=uint8
        VOUTP_VCULife1_cnt: implementation-data-type=uint8
        VOUTP_VCULife2_cnt: implementation-data-type=uint8
        VOUTP_VSPFunc_enum: implementation-data-type=uint8
        VOUTP_VSPIGNKeySta_enum: implementation-data-type=uint8
        VOUTP_VSPReversed_flg: implementation-data-type=boolean
        VOUTP_VSPTurnRight_enum: implementation-data-type=uint8
        VOUTP_VSPTurnLeft_enum: implementation-data-type=uint8
        VOUTP_FogTMSRlyCMD_enum: implementation-data-type=uint8
        VOUTP_DCCurr_A: implementation-data-type=float32
        VOUTP_DCVol_V: implementation-data-type=float32
        VOUTP_Keystatus_enum: implementation-data-type=uint8
        VOUTP_EmergencyShutDown_flg: implementation-data-type=boolean
        VOUTP_triggerBAM_flg: implementation-data-type=boolean
        VOUTP_CFGEM1Ctrl_raw: implementation-data-type=uint8
        VOUTP_CFGEM1BAMTSize_raw: implementation-data-type=uint16
        VOUTP_CFGEM1BAMTNum_raw: implementation-data-type=uint8
        VOUTP_CFGEM1BAMRsv_raw: implementation-data-type=uint8
        VOUTP_CFGEM1BAMPGN_raw: implementation-data-type=uint32
        VOUTP_triggerDT_flg: implementation-data-type=boolean
        VOUTP_DTbyte{0..7}_raw: implementation-data-type=uint8
        VOUTP_HWVer{1..3}_cnt: implementation-data-type=uint8
        VOUTP_CarModel{1..3}_cnt: implementation-data-type=uint8
        VOUTP_ECU1_cnt: implementation-data-type=uint8
        VOUTP_ECU2_cnt: implementation-data-type=uint8
        VOUTP_Major1_cnt: implementation-data-type=uint8
        VOUTP_Major2_cnt: implementation-data-type=uint8
        VOUTP_Minor1_cnt: implementation-data-type=uint8
        VOUTP_Minor2_cnt: implementation-data-type=uint8
        VOUTP_Patch1_cnt: implementation-data-type=uint8
        VOUTP_Patch2_cnt: implementation-data-type=uint8
        VOUTP_Country1_cnt: implementation-data-type=uint8
        VOUTP_Country2_cnt: implementation-data-type=uint8
        VOUTP_Variation_cnt: implementation-data-type=uint8
        VOUTP_Dash1_cnt: implementation-data-type=uint8
        VOUTP_Change1_cnt: implementation-data-type=uint8
        VOUTP_Change2_cnt: implementation-data-type=uint8
        VOUTP_Dash2_cnt: implementation-data-type=uint8
        VOUTP_SHA{1..8}_cnt: implementation-data-type=uint8
        VOUTP_NvWriteReqRisingEdge_flg: implementation-data-type=boolean
        VOUTP_FdcSlpReqRisingEdge_flg: implementation-data-type=boolean
        VOUTP_FdcSlpTime_sec: implementation-data-type=float32
        VOUTP_PmicBootReason_enum: implementation-data-type=uint8
        VOUTP_WisrBootReason_raw32: implementation-data-type=uint32
        VOUTP_AcoreRebootCmdACK_flg: implementation-data-type=boolean
        VOUTP_CurrentNmState_enum: implementation-data-type=uint8
        VOUTP_ECUGen1_cnt: implementation-data-type=uint8
        VOUTP_ECUGen2_cnt: implementation-data-type=uint8
        VOUTP_PmicBootPath_raw32: implementation-data-type=uint32
        VOUTP_DrivingMode_cnt: implementation-data-type=uint8
        VOUTP_ModelYear_cnt: implementation-data-type=uint8
        VOUTP_EWPPEReq_rpm: implementation-data-type=float32
        VOUTP_CoolFanReq_pct: implementation-data-type=float32
        VOUTP_AfterrunningMode_flg: implementation-data-type=boolean
        VOUTP_LFBatWarn_flg: implementation-data-type=boolean
        VOUTP_RFBatWarn_flg: implementation-data-type=boolean
        VOUTP_LRBatWarn_flg: implementation-data-type=boolean
        VOUTP_RRBatWarn_flg: implementation-data-type=boolean
        VOUTP_LFWheelPress_raw8: implementation-data-type=uint8
        VOUTP_RFWheelPress_raw8: implementation-data-type=uint8
        VOUTP_LRWheelPress_raw8: implementation-data-type=uint8
        VOUTP_RRWheelPress_raw8: implementation-data-type=uint8
        VOUTP_LFWheelTemp_C: implementation-data-type=float32
        VOUTP_RFWheelTemp_C: implementation-data-type=float32
        VOUTP_LRWheelTemp_C: implementation-data-type=float32
        VOUTP_RRWheelTemp_C: implementation-data-type=float32
        VOUTP_LFSensorFail_flg: implementation-data-type=boolean
        VOUTP_RFSensorFail_flg: implementation-data-type=boolean
        VOUTP_LRSensorFail_flg: implementation-data-type=boolean
        VOUTP_RRSensorFail_flg: implementation-data-type=boolean
        VOUTP_LFWheelDebug_flg: implementation-data-type=boolean
        VOUTP_LRWheelDebug_flg: implementation-data-type=boolean
        VOUTP_RFWheelDebug_flg: implementation-data-type=boolean
        VOUTP_RRWheelDebug_flg: implementation-data-type=boolean
        VOUTP_TPMSResButtAllow_flg: implementation-data-type=boolean
        VOUTP_TPMSCaliButtAllow_flg: implementation-data-type=boolean
        VOUTP_LFPressIndi_enum: implementation-data-type=uint8
        VOUTP_RFPressIndi_enum: implementation-data-type=uint8
        VOUTP_LRPressIndi_enum: implementation-data-type=uint8
        VOUTP_RRPressIndi_enum: implementation-data-type=uint8
        VOUTP_TPMSWarnIndi_enum: implementation-data-type=uint8
        VOUTP_LFWheelTmpIndi_flg: implementation-data-type=boolean
        VOUTP_RFWheelTmpIndi_flg: implementation-data-type=boolean
        VOUTP_LRWheelTmpIndi_flg: implementation-data-type=boolean
        VOUTP_RRWheelTmpIndi_flg: implementation-data-type=boolean
        VOUTP_LFWheelPSW_raw8: implementation-data-type=uint8
        VOUTP_LRWheelPSW_raw8: implementation-data-type=uint8
        VOUTP_RFWheelPSW_raw8: implementation-data-type=uint8
        VOUTP_RRWheelPSW_raw8: implementation-data-type=uint8
        VOUTP_CWheelTips_enum: implementation-data-type=uint8
        VOUTP_AutoLTips_enum: implementation-data-type=uint8
        VOUTP_LFSensorMode_flg: implementation-data-type=boolean
        VOUTP_RFSensorMode_flg: implementation-data-type=boolean
        VOUTP_LRSensorMode_flg: implementation-data-type=boolean
        VOUTP_RRSensorMode_flg: implementation-data-type=boolean
        VOUTP_S{1..4}ID_raw32: implementation-data-type=uint32
        VOUTP_S{1..4}L_enum: implementation-data-type=uint8
        VOUTP_ALFin_flg: implementation-data-type=boolean
        VOUTP_LFP20_raw8: implementation-data-type=uint8
        VOUTP_RFP20_raw8: implementation-data-type=uint8
        VOUTP_LRP20_raw8: implementation-data-type=uint8
        VOUTP_RRP20_raw8: implementation-data-type=uint8
        VOUTP_FAT_flg: implementation-data-type=boolean
        VOUTP_IDin_raw32: implementation-data-type=uint32
        VOUTP_S{1..4}WheelDebugALTU_pct: implementation-data-type=float32
        VOUTP_ID{1..4}messageALTU_raw8: implementation-data-type=uint8
        VOUTP_Chkfin_flg: implementation-data-type=boolean
        VOUTP_SetIDLoc_flg: implementation-data-type=boolean
        VOUTP_TPMSStorge_flg: implementation-data-type=boolean
        VOUTP_ChkStorge_flg: implementation-data-type=boolean
        VOUTP_TPMSResButt_flg: implementation-data-type=boolean
        VOUTP_LFPindi_enum: implementation-data-type=uint8
        VOUTP_RFPind_enum: implementation-data-type=uint8
        VOUTP_LRPindi_enum: implementation-data-type=uint8
        VOUTP_RRPindi_enum: implementation-data-type=uint8
        VOUTP_WriteChkLFID_raw: implementation-data-type=uint32
        VOUTP_WriteChkRFID_raw: implementation-data-type=uint32
        VOUTP_WriteChkLRID_raw: implementation-data-type=uint32
        VOUTP_WriteChkRRID_raw: implementation-data-type=uint32
        VOUTP_WriteChkfinLFID_raw: implementation-data-type=uint32
        VOUTP_WriteChkfinRFID_raw: implementation-data-type=uint32
        VOUTP_WriteChkfinLRID_raw: implementation-data-type=uint32
        VOUTP_WriteChkfinRRID_raw: implementation-data-type=uint32
        VOUTP_Flashchkdatavalid_enum: implementation-data-type=uint8
        VOUTP_Flashdatavalid_enum: implementation-data-type=uint8
        VOUTP_unlearnSfali_flg: implementation-data-type=boolean
        VOUTP_unlearnSfailvalid_enum: implementation-data-type=uint8
        VOUTP_Prepresstempvalid_enum: implementation-data-type=uint8
        VOUTP_FlashS{1..4}ID_raw: implementation-data-type=uint32
        VOUTP_FlashIDvalid_enum: implementation-data-type=uint8
        VOUTP_WritingCnt_enum: implementation-data-type=uint8
        VOUTP_TPMSTLCmd_flg: implementation-data-type=boolean
        VOUTP_LProgress_enum: implementation-data-type=uint8
        VOUTP_TPMSSensorIDRegStart_flg: implementation-data-type=boolean
        VOUTP_ModelVersion_raw: implementation-data-type=uint8
        VOUTP_ModelVersionChksum_raw: implementation-data-type=uint8
        VOUTP_VCUMCUCtrlMdTQD_enum: implementation-data-type=uint8
        VOUTP_CreepSpdReq_rpm: implementation-data-type=float32
        VOUTP_CreepIND_enum: implementation-data-type=uint8
        VOUTP_ActTUpAIND_enum: implementation-data-type=uint8
        VOUTP_VCUMCUDemHiPosVal_rpm: implementation-data-type=float32
        VOUTP_VehAcclLimitTG_mps2: implementation-data-type=float32
        VOUTP_VCUEBSHHSw_enum: implementation-data-type=uint8
        VOUTP_VCUEBSRd4BR_enum: implementation-data-type=uint8
        VOUTP_ParkingProtectWarning_flg: implementation-data-type=boolean
        VOUTP_ActDriveMode_enum: implementation-data-type=uint8
        VOUTP_VCU4PweLmtInd_flg: implementation-data-type=boolean
        VOUTP_GearFlashIndDis_flg: implementation-data-type=boolean
        VOUTP_GearFlashInd_flg: implementation-data-type=boolean
        VOUTP_SpdLimSta_flg: implementation-data-type=boolean
        VOUTP_VehSpdLimitTG_kph: implementation-data-type=float32
        VOUTP_VCUTMVehSpd_kph: implementation-data-type=float32
        VOUTP_TMTqReq_Nm: implementation-data-type=float32
        VOUTP_VCUBCMBuzzReq_flg: implementation-data-type=boolean
        VOUTP_VCUEBSHBSw_enum: implementation-data-type=uint8
        VOUTP_EVCU1ActDrvMode_enum: implementation-data-type=uint8
        VOUTP_EVCU1WheelSlipdet_enum: implementation-data-type=uint8
        VOUTP_EVCU1EMotorSpd_rpm: implementation-data-type=float32
        VOUTP_EVCU1EMotorOvrerSpd_enum: implementation-data-type=uint8
        VOUTP_EVCU1EMotorPerformance_pct: implementation-data-type=float32
        VOUTP_EVCU1EBrakeTorqLow_enum: implementation-data-type=uint8
        VOUTP_EVCU2MaxTorqAvail_pct: implementation-data-type=float32
        VOUTP_EVCU2MinTorqAvail_pct: implementation-data-type=float32
        VOUTP_EEC3NFricPercTorq_pct: implementation-data-type=float32
        VOUTP_EEC3EMPressLoss_pct: implementation-data-type=float32
        VOUTP_ETC2ActDriveDirect_enum: implementation-data-type=float32
        VOUTP_RC1PctTrqP4_pct: implementation-data-type=float32
        VOUTP_RC1PctTrqPekTrqP5_pct: implementation-data-type=float32
        VOUTP_EMRC1EMTquModeDrvBrk_enum: implementation-data-type=uint8
        VOUTP_EMRC1ActEMpTrq_pct: implementation-data-type=float32
        VOUTP_EMRC1ActEMOutSftSpd_rpm: implementation-data-type=float32
        VOUTP_EMRC1ActEMpTrqHrls_pct: implementation-data-type=float32
        VOUTP_EMRC1ActMaxAvaEMRecpTrq_pct: implementation-data-type=float32
        VOUTP_EC1EMSpdIdleP1_rpm: implementation-data-type=float32
        VOUTP_EC1PercTorqIdleP1_pct: implementation-data-type=float32
        VOUTP_EC1EMSpdIdleP2_rpm: implementation-data-type=float32
        VOUTP_EC1PercTorqIdleP2_pct: implementation-data-type=float32
        VOUTP_EC1EMSpdIdleP3_rpm: implementation-data-type=float32
        VOUTP_EC1PercTorqIdleP3_pct: implementation-data-type=float32
        VOUTP_EC1EMSpdIdleP4_rpm: implementation-data-type=float32
        VOUTP_EC1PercTorqIdleP4_pct: implementation-data-type=float32
        VOUTP_EC1PercTorqIdleP5_pct: implementation-data-type=float32
        VOUTP_EC1EMSpdIdleP5_rpm: implementation-data-type=float32
        VOUTP_EC1EMRefTorq_Nm: implementation-data-type=float32
        VOUTP_EC1EMMaxMEngOvrSP7_rpm: implementation-data-type=float32
        VOUTP_EC1EMMaxMOvrTmt_s: implementation-data-type=float32
        VOUTP_EC1EMReqSpdCtrlLoLmt_rpm: implementation-data-type=float32
        VOUTP_EC1EMReqTrqCtrlLoLmt_pct: implementation-data-type=float32
        VOUTP_EC1EMReqSpdCtrlUpLmt_rpm: implementation-data-type=float32
        VOUTP_EC1EMReqTrqCtrlUpLmt_pct: implementation-data-type=float32
        VOUTP_EC1EMExtRSCtrlUpLmt_rpm: implementation-data-type=float32
        VOUTP_EC1EMMomOfInertia_kgpm2: implementation-data-type=float32
        VOUTP_EC1EMDefTrqLmt_rpm: implementation-data-type=float32
        VOUTP_EC1EMSupVarRTSC1MSG_cnt: implementation-data-type=uint8
        VOUTP_EC1EMSupTSC1CtrlPG1_cnt: implementation-data-type=uint8
        VOUTP_EC1EMSupTSC1CtrlPG3_cnt: implementation-data-type=uint8
        VOUTP_EC1EMSupTSC1CtrlPG2_cnt: implementation-data-type=uint8
        VOUTP_EC1EMSupTSC1CtrlPG4_cnt: implementation-data-type=uint8
        VOUTP_EC1EMSpdHdleP6_rpm: implementation-data-type=float32
        VOUTP_EC1EMGainEndSpdGvn_gain: implementation-data-type=float32
        VOUTP_RC1RetType_enum: implementation-data-type=uint8
        VOUTP_RC1RetLocat_enum: implementation-data-type=uint8
        VOUTP_RC1RetCtrlMth_enum: implementation-data-type=float32
        VOUTP_RC1RetSpdIdleP1_rpm: implementation-data-type=float32
        VOUTP_RC1PctTrqIdleP1_pct: implementation-data-type=float32
        VOUTP_RC1MaxRetSpdP2_rpm: implementation-data-type=float32
        VOUTP_RC1RetSpdP2_pct: implementation-data-type=float32
        VOUTP_RC1MaxRetSpdP3_rpm: implementation-data-type=float32
        VOUTP_RC1PctTrqP3_pct: implementation-data-type=float32
        VOUTP_RC1RefRetTrq_Nm: implementation-data-type=float32
        VOUTP_RC1RetSpdPekTrqP5_Nm: implementation-data-type=float32
        VOUTP_RC1RetSpdP4_rpm: implementation-data-type=float32
        VOUTP_VCUMCUDemLoNegVal_rpm: implementation-data-type=float32
        VOUTP_VCUMCUDemSpd_rpm: implementation-data-type=float32
        VOUTP_VCUMCUGearSta_enum: implementation-data-type=uint8
        VOUTP_TUpAIND_enum: implementation-data-type=uint8
        VOUTP_ETC1ShiftrPgs_enum: implementation-data-type=uint8
        VOUTP_EVCU1RecuperHighSta_enum: implementation-data-type=uint8
        VOUTP_EMRC1DrvDemEMRtapTrq_pct: implementation-data-type=float32
        VOUTP_EMRC1RetSelNonEng_pct: implementation-data-type=float32
        VOUTP_EMRC1SACtrlDev_cnt: implementation-data-type=uint8
        VOUTP_VCUMCUHandBrk_flg: implementation-data-type=boolean
        VOUTP_VCUMCUFootBrk_flg: implementation-data-type=boolean
        VOUTP_FrTMTqReq_Nm: implementation-data-type=float32
        VOUTP_RrTMTqReq_Nm: implementation-data-type=float32
        VOUTP_ReqOBCV2LEna_enum: implementation-data-type=uint8
        VOUTP_ReqV2LIVIPopup_enum: implementation-data-type=uint8
        VOUTP_ReqV2LIVIDisChrg_enum: implementation-data-type=uint8
        VOUTP_ReqOBCExtrV2LEna_enum: implementation-data-type=uint8
        VOUTP_ReqOBCIntrV2LEna_enum: implementation-data-type=uint8
        VOUTP_HVPO120VGrpALDSt_enum: implementation-data-type=uint8
        VOUTP_HVPO120VGrpBLDSt_enum: implementation-data-type=uint8
        VOUTP_FeatSetSpdFinal_raw32: implementation-data-type=float32
        VOUTP_VehicleSpeed_mph: implementation-data-type=float32
        VOUTP_VehicleSpeed_kph: implementation-data-type=float32
        VOUTP_MeterIndSpeed_raw32: implementation-data-type=float32
        VOUTP_VMCAEBCtrlAvail_flg: implementation-data-type=boolean
        VOUTP_VMCACCCtrlAvail_flg: implementation-data-type=boolean
        VOUTP_VMCCCCtrlAvail_flg: implementation-data-type=boolean
        VOUTP_VMCMSACtrlAvail_flg: implementation-data-type=boolean
        VOUTP_FeatArbitrSta_enum: implementation-data-type=uint8
        VOUTP_FeatReqSpd_kph: implementation-data-type=float32
        VOUTP_JerkPCT_pct: implementation-data-type=float32
        VOUTP_LimitPCT_pct: implementation-data-type=float32
        VOUTP_FrontRearSlipRatioCtrl_flg: implementation-data-type=boolean
        VOUTP_RearWhlSlipRatioCtrl_flg: implementation-data-type=boolean
        VOUTP_SingleWhlSlipRatioCtrl_flg: implementation-data-type=boolean
        VOUTP_LatAccCtrl_flg: implementation-data-type=boolean
        VOUTP_SafetyCtrl_flg: implementation-data-type=boolean
        VOUTP_SPD2ACCAct_flg: implementation-data-type=boolean
        VOUTP_AccCalcuPID_mps2: implementation-data-type=float32
        VOUTP_ISOAccLimit_mps2: implementation-data-type=float32
        VOUTP_ISODecLimit_mps2: implementation-data-type=float32
        VOUTP_ISOJerkLimit_mps3: implementation-data-type=float32
        VOUTP_ACCRequiredAccel_mps2: implementation-data-type=float32
        VOUTP_DISCReqAcc_mps2: implementation-data-type=float32
        VOUTP_FeatArbitrFinal_enum: implementation-data-type=uint8
        VOUTP_ActACCRequiredAccel_mps2: implementation-data-type=float32
        VOUTP_LateralCtrl_flg: implementation-data-type=boolean
        VOUTP_ADASLKASta_enum: implementation-data-type=uint8
        VOUTP_LKAStrToqReq_Nm: implementation-data-type=float32
        VOUTP_LKATOIFault_flg: implementation-data-type=boolean
        VOUTP_LKATOIAct_enum: implementation-data-type=uint8
        VOUTP_ADASAEBReq_enum: implementation-data-type=uint8
        VOUTP_ADASFaultSta_flg: implementation-data-type=boolean
        VOUTP_AEBVehHoldReq_flg: implementation-data-type=boolean
        VOUTP_ACCVehHoldReq_flg: implementation-data-type=boolean
        VOUTP_ADASDBSReq_enum: implementation-data-type=uint8
        VOUTP_ADASACCSta_enum: implementation-data-type=uint8
        VOUTP_ACCObjDist_m: implementation-data-type=float32
        VOUTP_ACCObjRelSpd_mps: implementation-data-type=float32
        VOUTP_TimeGapLevel_enum: implementation-data-type=uint8
        VOUTP_ACCJerkUpperLimit_mps3: implementation-data-type=float32
        VOUTP_ACCComfortBandUpper_mps2: implementation-data-type=float32
        VOUTP_ACCJerkLowerLimit_mps3: implementation-data-type=float32
        VOUTP_ACCComfortBandLower_mps2: implementation-data-type=float32
        VOUTP_ADASVehSpdLim_raw32: implementation-data-type=float32
        VOUTP_ADASShftPosnReqA_flg: implementation-data-type=boolean
        VOUTP_ADASShftPosnReq_enum: implementation-data-type=uint8
        VOUTP_ADASForceIdle_flg: implementation-data-type=boolean
        VOUTP_HazardWarningReq_flg: implementation-data-type=boolean
        VOUTP_RightTurnLightReq_flg: implementation-data-type=boolean
        VOUTP_LeftTurnLightReq_flg: implementation-data-type=boolean
        VOUTP_ADASFCWSta_enum: implementation-data-type=uint8
        VOUTP_ADASLDWSta_enum: implementation-data-type=uint8
        VOUTP_ADASFltWrnReq_flg: implementation-data-type=boolean
        VOUTP_ACCObjDstLvl_enum: implementation-data-type=uint8
        VOUTP_ForceLowBeam_enum: implementation-data-type=uint8
        VOUTP_ACCTakeoverReq_flg: implementation-data-type=boolean
        VOUTP_ADASWarningMsg_enum: implementation-data-type=uint8
        VOUTP_ADASCAMSpdLim_enum: implementation-data-type=uint8
        VOUTP_TargetType_enum: implementation-data-type=uint8
        VOUTP_ADASSLIFSpdLim_enum: implementation-data-type=uint8
        VOUTP_LKAHODDisplayWarning_flg: implementation-data-type=boolean
        VOUTP_LKAHODSoundWarning_flg: implementation-data-type=boolean
        VOUTP_ADASLFCSta_enum: implementation-data-type=uint8
        VOUTP_ADASLaneModeL_enum: implementation-data-type=uint8
        VOUTP_ADASLaneModeR_enum: implementation-data-type=uint8
        VOUTP_ADASSLIFSta_enum: implementation-data-type=uint8
        VOUTP_ADASISASta_enum: implementation-data-type=uint8
        VOUTP_ADASLDWMute_flg: implementation-data-type=boolean
        VOUTP_ADASFCWMute_flg: implementation-data-type=boolean
        VOUTP_ADASLFCHandsOffWarning_enum: implementation-data-type=uint8
        VOUTP_LVDADisabled_flg: implementation-data-type=boolean
        VOUTP_LVDAMuteSta_enum: implementation-data-type=uint8
        VOUTP_LVDAFailinfo_flg: implementation-data-type=boolean
        VOUTP_LVDAWarning_flg: implementation-data-type=boolean
        VOUTP_LVDAACCStatusInformation_flg: implementation-data-type=boolean
        VOUTP_ADASLFCWarnSound_enum: implementation-data-type=uint8
        VOUTP_FCMACCmode_enum: implementation-data-type=uint8
        VOUTP_ADASLanetypeR_enum: implementation-data-type=uint8
        VOUTP_ADASLanetypeL_enum: implementation-data-type=uint8
        VOUTP_ADASLanecurveL_raw32: implementation-data-type=float32
        VOUTP_ADASLanecurveR_raw32: implementation-data-type=float32
        VOUTP_ADASAEBSta_enum: implementation-data-type=uint8
        VOUTP_FCMLDWRequest_enum: implementation-data-type=uint8
        VOUTP_FCMLDWFault_flg: implementation-data-type=boolean
        VOUTP_ACCCtrlAvail_flg: implementation-data-type=boolean
        VOUTP_ACCPedalOvrd_flg: implementation-data-type=boolean
        VOUTP_TimeGapCalcu_s: implementation-data-type=float32
        VOUTP_CCCtrlSta_enum: implementation-data-type=uint8
        VOUTP_MSACtrlSta_enum: implementation-data-type=uint8
        VOUTP_APSCtrlAvail_flg: implementation-data-type=boolean
        VOUTP_APSActive_flg: implementation-data-type=boolean
        VOUTP_APSStaSys_enum: implementation-data-type=uint8
        VOUTP_APSDecReqA_flg: implementation-data-type=boolean
        VOUTP_APSDecReq_mps2: implementation-data-type=float32
        VOUTP_APSReq_enum: implementation-data-type=uint8
        VOUTP_LongAcc_Gps: implementation-data-type=float32
        VOUTP_CCMSASpdWar_flg: implementation-data-type=boolean
        VOUTP_IMUEnaCmd_flg: implementation-data-type=boolean
        VOUTP_CAASCtrlAvail_flg: implementation-data-type=boolean
        VOUTP_CAASActive_flg: implementation-data-type=boolean
        VOUTP_ExtraMSACtrlSta_enum: implementation-data-type=uint8
        VOUTP_CalibratedAccX_G: implementation-data-type=float32
        VOUTP_CalibratedAccY_G: implementation-data-type=float32
        VOUTP_CalibratedAccZ_G: implementation-data-type=float32
        VOUTP_CalibratedGyroX_Dps: implementation-data-type=float32
        VOUTP_CalibratedGyroY_Dps: implementation-data-type=float32
        VOUTP_CalibratedGyroZ_Dps: implementation-data-type=float32
        VOUTP_FDCVMCAPSVRqEPSCtrl_flg: implementation-data-type=boolean
        VOUTP_FDCVMCAPSAngleTarget_deg: implementation-data-type=float32
        VOUTP_FDCVMCAPSRqEPSCtrl_flg: implementation-data-type=boolean
        VOUTP_FDCVMCAngCtrlTqWtGn_pct: implementation-data-type=float32
        VOUTP_FDCVMCDrInpTqBstAct_flg: implementation-data-type=boolean
        VOUTP_FDCVMCMaxAngCtrlOutTqLim_Nm: implementation-data-type=float32
        VOUTP_FDCVMCDrInpTqBstGn_pct: implementation-data-type=float32
    u8_Array16_type: category=ARRAY
      element u8_Array16: category=VALUE, array-size=16, array-size-semantics=FIXED-SIZE, base-type=uint8
    u8_Array8_type: category=ARRAY
      element u8_Array8: category=VALUE, array-size=8, array-size-semantics=FIXED-SIZE, base-type=uint8
    u16_Array8_type: category=ARRAY
      element u16_Array8: category=VALUE, array-size=8, array-size-semantics=FIXED-SIZE, base-type=uint16
    u32_Array8_type: category=ARRAY
      element u32_Array8: category=VALUE, array-size=8, array-size-semantics=FIXED-SIZE, base-type=uint32
    u8_Array17_type: category=ARRAY
      element u8_Array17: category=VALUE, array-size=17, array-size-semantics=FIXED-SIZE, base-type=uint8
package /Interface_OUTP_ARPkg
  sender receiver interface IF_BOUTP_outputs
    data BOUTP_outputs: type=BOUTP_outputs
package /SWC_OUTP_ARPkg
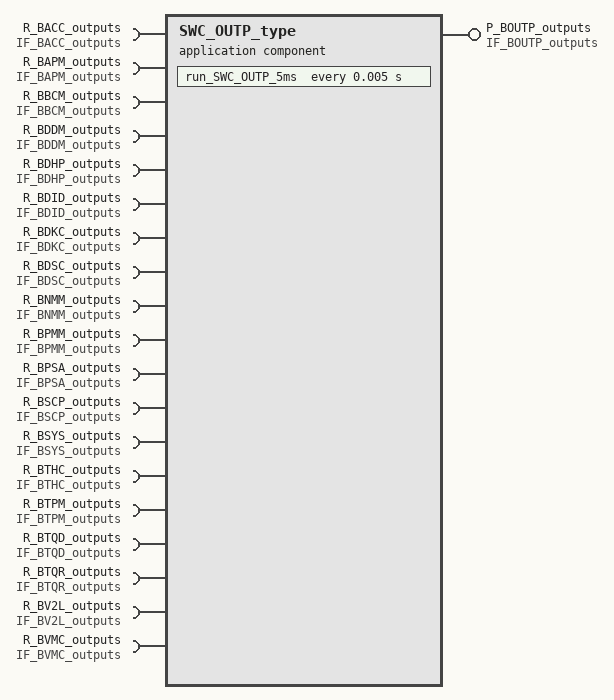
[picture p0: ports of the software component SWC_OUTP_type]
  application sw component type SWC_OUTP_type
    provide port P_BOUTP_outputs: provided-interface=IF_BOUTP_outputs
    19 x require port:
      R_BACC_outputs: required-interface=IF_BACC_outputs
      R_BAPM_outputs: required-interface=IF_BAPM_outputs
      R_BBCM_outputs: required-interface=IF_BBCM_outputs
      R_BDDM_outputs: required-interface=IF_BDDM_outputs
      R_BDHP_outputs: required-interface=IF_BDHP_outputs
      R_BDID_outputs: required-interface=IF_BDID_outputs
      R_BDKC_outputs: required-interface=IF_BDKC_outputs
      R_BDSC_outputs: required-interface=IF_BDSC_outputs
      R_BNMM_outputs: required-interface=IF_BNMM_outputs
      R_BPMM_outputs: required-interface=IF_BPMM_outputs
      R_BPSA_outputs: required-interface=IF_BPSA_outputs
      R_BSCP_outputs: required-interface=IF_BSCP_outputs
      R_BSYS_outputs: required-interface=IF_BSYS_outputs
      R_BTHC_outputs: required-interface=IF_BTHC_outputs
      R_BTPM_outputs: required-interface=IF_BTPM_outputs
      R_BTQD_outputs: required-interface=IF_BTQD_outputs
      R_BTQR_outputs: required-interface=IF_BTQR_outputs
      R_BV2L_outputs: required-interface=IF_BV2L_outputs
      R_BVMC_outputs: required-interface=IF_BVMC_outputs
    behavior SWC_OUTP_type_IB: handle-termination-and-restart=NO-SUPPORT
      timing event TE_OUTP_5ms: start-on-event=run_SWC_OUTP_5ms, period=0.005
      runnable run_SWC_OUTP_5ms
        data-receive-point-by-arguments:
          19 x access:
            drparg_BACC_outputs: accessed-variable=R_BACC_outputs.BACC_outputs
            drparg_BAPM_outputs: accessed-variable=R_BAPM_outputs.BAPM_outputs
            drparg_BBCM_outputs: accessed-variable=R_BBCM_outputs.BBCM_outputs
            drparg_BDDM_outputs: accessed-variable=R_BDDM_outputs.BDDM_outputs
            drparg_BDHP_outputs: accessed-variable=R_BDHP_outputs.BDHP_outputs
            drparg_BDID_outputs: accessed-variable=R_BDID_outputs.BDID_outputs
            drparg_BDKC_outputs: accessed-variable=R_BDKC_outputs.BDKC_outputs
            drparg_BDSC_outputs: accessed-variable=R_BDSC_outputs.BDSC_outputs
            drparg_BNMM_outputs: accessed-variable=R_BNMM_outputs.BNMM_outputs
            drparg_BPMM_outputs: accessed-variable=R_BPMM_outputs.BPMM_outputs
            drparg_BPSA_outputs: accessed-variable=R_BPSA_outputs.BPSA_outputs
            drparg_BSCP_outputs: accessed-variable=R_BSCP_outputs.BSCP_outputs
            drparg_BSYS_outputs: accessed-variable=R_BSYS_outputs.BSYS_outputs
            drparg_BTHC_outputs: accessed-variable=R_BTHC_outputs.BTHC_outputs
            drparg_BTPM_outputs: accessed-variable=R_BTPM_outputs.BTPM_outputs
            drparg_BTQD_outputs: accessed-variable=R_BTQD_outputs.BTQD_outputs
            drparg_BTQR_outputs: accessed-variable=R_BTQR_outputs.BTQR_outputs
            drparg_BV2L_outputs: accessed-variable=R_BV2L_outputs.BV2L_outputs
            drparg_BVMC_outputs: accessed-variable=R_BVMC_outputs.BVMC_outputs
        data-send-points:
          access dsp_BOUTP_outputs: accessed-variable=P_BOUTP_outputs.BOUTP_outputs
